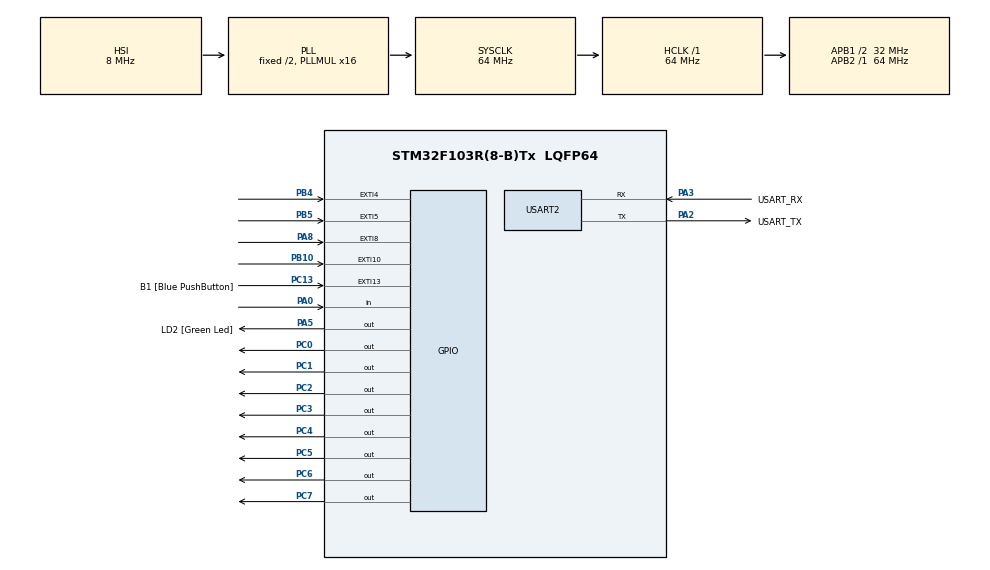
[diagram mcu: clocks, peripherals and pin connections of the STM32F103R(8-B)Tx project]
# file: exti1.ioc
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Mcu.Family=STM32F1
Mcu.Name=STM32F103R(8-B)Tx
Mcu.Package=LQFP64
NVIC.EXTI15_10_IRQn=true\:0\:0\:false\:false\:true\:true
NVIC.EXTI4_IRQn=true\:0\:0\:false\:false\:true\:true
NVIC.EXTI9_5_IRQn=true\:0\:0\:false\:false\:true\:true
NVIC.PriorityGroup=NVIC_PRIORITYGROUP_4
PA0-WKUP.Signal=GPIO_Input
PA13.GPIO_Label=TMS
PA13.Mode=Serial_Wire
PA13.Signal=SYS_JTMS-SWDIO
PA14.GPIO_Label=TCK
PA14.Mode=Serial_Wire
PA14.Signal=SYS_JTCK-SWCLK
PA2.GPIO_Label=USART_TX
PA2.GPIO_Mode=GPIO_MODE_AF_PP
PA2.GPIO_PuPd=GPIO_NOPULL
PA2.GPIO_Speed=GPIO_SPEED_FREQ_LOW
PA2.Mode=Asynchronous
PA2.Signal=USART2_TX
PA3.GPIO_Label=USART_RX
PA3.GPIO_Mode=GPIO_MODE_AF_PP
PA3.GPIO_PuPd=GPIO_NOPULL
PA3.GPIO_Speed=GPIO_SPEED_FREQ_LOW
PA3.Mode=Asynchronous
PA3.Signal=USART2_RX
PA5.GPIO_Label=LD2 [Green Led]
PA5.GPIO_ModeDefaultOutputPP=GPIO_MODE_OUTPUT_PP
PA5.GPIO_PuPd=GPIO_NOPULL
PA5.GPIO_Speed=GPIO_SPEED_FREQ_LOW
PA5.Signal=GPIO_Output
PA8.Signal=GPXTI8
PB10.Signal=GPXTI10
PB3.GPIO_Label=SWO
PB3.Signal=SYS_JTDO-TRACESWO
PB4.Signal=GPXTI4
PB5.Signal=GPXTI5
PC0.Signal=GPIO_Output
PC1.Signal=GPIO_Output
PC13-TAMPER-RTC.GPIO_Label=B1 [Blue PushButton]
PC13-TAMPER-RTC.GPIO_PuPd=GPIO_NOPULL
PC13-TAMPER-RTC.Signal=GPXTI13
PC14-OSC32_IN.Mode=LSE-External-Oscillator
PC14-OSC32_IN.Signal=RCC_OSC32_IN
PC15-OSC32_OUT.Mode=LSE-External-Oscillator
PC15-OSC32_OUT.Signal=RCC_OSC32_OUT
PC2.Signal=GPIO_Output
PC3.Signal=GPIO_Output
PC4.Signal=GPIO_Output
PC5.Signal=GPIO_Output
PC6.Signal=GPIO_Output
PC7.Signal=GPIO_Output
PD0-OSC_IN.Mode=HSE-External-Clock-Source
PD0-OSC_IN.Signal=RCC_OSC_IN
PD1-OSC_OUT.Mode=HSE-External-Clock-Source
PD1-OSC_OUT.Signal=RCC_OSC_OUT
ProjectManager.HeapSize=0x200
ProjectManager.StackSize=0x400
ProjectManager.TargetToolchain=MDK-ARM V5
RCC.AHBFreq_Value=64000000
RCC.APB1CLKDivider=RCC_HCLK_DIV2
RCC.APB1Freq_Value=32000000
RCC.APB1TimFreq_Value=64000000
RCC.APB2Freq_Value=64000000
RCC.APB2TimFreq_Value=64000000
RCC.HCLKFreq_Value=64000000
RCC.PLLMUL=RCC_PLL_MUL16
RCC.RTCClockSelection=RCC_RTCCLKSOURCE_LSE
RCC.SYSCLKFreq_VALUE=64000000
RCC.SYSCLKSource=RCC_SYSCLKSOURCE_PLLCLK
RCC.USBFreq_Value=64000000
USART2.VirtualMode=VM_ASYNC
board=NUCLEO-F103RB

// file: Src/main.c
/**
  ******************************************************************************
  * @file           : main.c
  * @brief          : Main program body
  ******************************************************************************
  ** This notice applies to any and all portions of this file
  * that are not between comment pairs USER CODE BEGIN and
  * USER CODE END. Other portions of this file, whether
  * inserted by the user or by software development tools
  * are owned by their respective copyright owners.
  *
  * COPYRIGHT(c) 2019 STMicroelectronics
  *
  * Redistribution and use in source and binary forms, with or without modification,
  * are permitted provided that the following conditions are met:
  *   1. Redistributions of source code must retain the above copyright notice,
  *      this list of conditions and the following disclaimer.
  *   2. Redistributions in binary form must reproduce the above copyright notice,
  *      this list of conditions and the following disclaimer in the documentation
  *      and/or other materials provided with the distribution.
  *   3. Neither the name of STMicroelectronics nor the names of its contributors
  *      may be used to endorse or promote products derived from this software
  *      without specific prior written permission.
  *
  * THIS SOFTWARE IS PROVIDED BY THE COPYRIGHT HOLDERS AND CONTRIBUTORS "AS IS"
  * AND ANY EXPRESS OR IMPLIED WARRANTIES, INCLUDING, BUT NOT LIMITED TO, THE
  * IMPLIED WARRANTIES OF MERCHANTABILITY AND FITNESS FOR A PARTICULAR PURPOSE ARE
  * DISCLAIMED. IN NO EVENT SHALL THE COPYRIGHT HOLDER OR CONTRIBUTORS BE LIABLE
  * FOR ANY DIRECT, INDIRECT, INCIDENTAL, SPECIAL, EXEMPLARY, OR CONSEQUENTIAL
  * DAMAGES (INCLUDING, BUT NOT LIMITED TO, PROCUREMENT OF SUBSTITUTE GOODS OR
  * SERVICES; LOSS OF USE, DATA, OR PROFITS; OR BUSINESS INTERRUPTION) HOWEVER
  * CAUSED AND ON ANY THEORY OF LIABILITY, WHETHER IN CONTRACT, STRICT LIABILITY,
  * OR TORT (INCLUDING NEGLIGENCE OR OTHERWISE) ARISING IN ANY WAY OUT OF THE USE
  * OF THIS SOFTWARE, EVEN IF ADVISED OF THE POSSIBILITY OF SUCH DAMAGE.
  *
  ******************************************************************************
  */
#include "main.h"
#include "stm32f1xx_hal.h"

UART_HandleTypeDef huart2;

/* USER CODE BEGIN PV */

int flag_sw1, flag_sw2, flag_sw3, flag_sw4 = 0;
int SW1, SW2, SW3, SW4 = 0;

/* Private variables ---------------------------------------------------------*/

/* USER CODE END PV */

void SystemClock_Config(void);
static void MX_GPIO_Init(void);
static void MX_USART2_UART_Init(void);

/* USER CODE BEGIN PFP */
/* Private function prototypes -----------------------------------------------*/

/* USER CODE END PFP */

void HAL_GPIO_EXTI_Callback(uint16_t GPIO_PIN) {
	if (GPIO_PIN == GPIO_PIN_8) flag_sw1 = 1;
	if (GPIO_PIN == GPIO_PIN_4) flag_sw2=  1;
	if (GPIO_PIN == GPIO_PIN_5) flag_sw3 = 1;
	if (GPIO_PIN == GPIO_PIN_10)flag_sw4 = 1;
}

int main(void)
{
  HAL_Init();
  SystemClock_Config();
  MX_GPIO_Init();
  MX_USART2_UART_Init();
  while (1) {
		if(flag_sw1 == 1) {
			HAL_GPIO_WritePin(GPIOC, GPIO_PIN_0 | GPIO_PIN_1, GPIO_PIN_SET);
			HAL_Delay(200);
			HAL_GPIO_WritePin(GPIOC, GPIO_PIN_0 | GPIO_PIN_1, GPIO_PIN_RESET);
			flag_sw1 = 0;
		}
		if (flag_sw2 == 1) {
			HAL_GPIO_WritePin(GPIOC, GPIO_PIN_2 | GPIO_PIN_3, GPIO_PIN_SET);
			HAL_Delay(200);
			HAL_GPIO_WritePin(GPIOC, GPIO_PIN_2 | GPIO_PIN_3, GPIO_PIN_RESET);
			flag_sw2 = 0;
		}
		if (flag_sw3 == 1) {
			HAL_GPIO_WritePin(GPIOC, GPIO_PIN_4 | GPIO_PIN_5, GPIO_PIN_SET);
			HAL_Delay(200);
			HAL_GPIO_WritePin(GPIOC, GPIO_PIN_4 | GPIO_PIN_5, GPIO_PIN_RESET);
			flag_sw3 = 0;
		}
		if (flag_sw4 == 1) {
			HAL_GPIO_WritePin(GPIOC, GPIO_PIN_6 | GPIO_PIN_7, GPIO_PIN_SET);
			HAL_Delay(200);
			HAL_GPIO_WritePin(GPIOC, GPIO_PIN_6 | GPIO_PIN_7, GPIO_PIN_RESET);
			flag_sw4 = 0;
		}
  }

}

void SystemClock_Config(void)
{

  RCC_OscInitTypeDef RCC_OscInitStruct;
  RCC_ClkInitTypeDef RCC_ClkInitStruct;

    /**Initializes the CPU, AHB and APB busses clocks
    */
  RCC_OscInitStruct.OscillatorType = RCC_OSCILLATORTYPE_HSI;
  RCC_OscInitStruct.HSIState = RCC_HSI_ON;
  RCC_OscInitStruct.HSICalibrationValue = 16;
  RCC_OscInitStruct.PLL.PLLState = RCC_PLL_ON;
  RCC_OscInitStruct.PLL.PLLSource = RCC_PLLSOURCE_HSI_DIV2;
  RCC_OscInitStruct.PLL.PLLMUL = RCC_PLL_MUL16;
  if (HAL_RCC_OscConfig(&RCC_OscInitStruct) != HAL_OK)
  {
    _Error_Handler(__FILE__, __LINE__);
  }

    /**Initializes the CPU, AHB and APB busses clocks
    */
  RCC_ClkInitStruct.ClockType = RCC_CLOCKTYPE_HCLK|RCC_CLOCKTYPE_SYSCLK
                              |RCC_CLOCKTYPE_PCLK1|RCC_CLOCKTYPE_PCLK2;
  RCC_ClkInitStruct.SYSCLKSource = RCC_SYSCLKSOURCE_PLLCLK;
  RCC_ClkInitStruct.AHBCLKDivider = RCC_SYSCLK_DIV1;
  RCC_ClkInitStruct.APB1CLKDivider = RCC_HCLK_DIV2;
  RCC_ClkInitStruct.APB2CLKDivider = RCC_HCLK_DIV1;

  if (HAL_RCC_ClockConfig(&RCC_ClkInitStruct, FLASH_LATENCY_2) != HAL_OK)
  {
    _Error_Handler(__FILE__, __LINE__);
  }

    /**Configure the Systick interrupt time
    */
  HAL_SYSTICK_Config(HAL_RCC_GetHCLKFreq()/1000);

    /**Configure the Systick
    */
  HAL_SYSTICK_CLKSourceConfig(SYSTICK_CLKSOURCE_HCLK);

  /* SysTick_IRQn interrupt configuration */
  HAL_NVIC_SetPriority(SysTick_IRQn, 0, 0);
}

/* USART2 init function */
static void MX_USART2_UART_Init(void)
{

  huart2.Instance = USART2;
  huart2.Init.BaudRate = 115200;
  huart2.Init.WordLength = UART_WORDLENGTH_8B;
  huart2.Init.StopBits = UART_STOPBITS_1;
  huart2.Init.Parity = UART_PARITY_NONE;
  huart2.Init.Mode = UART_MODE_TX_RX;
  huart2.Init.HwFlowCtl = UART_HWCONTROL_NONE;
  huart2.Init.OverSampling = UART_OVERSAMPLING_16;
  if (HAL_UART_Init(&huart2) != HAL_OK)
  {
    _Error_Handler(__FILE__, __LINE__);
  }

}

/** Configure pins as
        * Analog
        * Input
        * Output
        * EVENT_OUT
        * EXTI
*/
static void MX_GPIO_Init(void)
{

  GPIO_InitTypeDef GPIO_InitStruct;

  /* GPIO Ports Clock Enable */
  __HAL_RCC_GPIOC_CLK_ENABLE();
  __HAL_RCC_GPIOD_CLK_ENABLE();
  __HAL_RCC_GPIOA_CLK_ENABLE();
  __HAL_RCC_GPIOB_CLK_ENABLE();

  /*Configure GPIO pin Output Level */
  HAL_GPIO_WritePin(GPIOC, GPIO_PIN_0|GPIO_PIN_1|GPIO_PIN_2|GPIO_PIN_3
                          |GPIO_PIN_4|GPIO_PIN_5|GPIO_PIN_6|GPIO_PIN_7, GPIO_PIN_RESET);

  /*Configure GPIO pin Output Level */
  HAL_GPIO_WritePin(LD2_GPIO_Port, LD2_Pin, GPIO_PIN_RESET);

  /*Configure GPIO pin : B1_Pin */
  GPIO_InitStruct.Pin = B1_Pin;
  GPIO_InitStruct.Mode = GPIO_MODE_IT_RISING;
  GPIO_InitStruct.Pull = GPIO_NOPULL;
  HAL_GPIO_Init(B1_GPIO_Port, &GPIO_InitStruct);

  /*Configure GPIO pins : PC0 PC1 PC2 PC3
                           PC4 PC5 PC6 PC7 */
  GPIO_InitStruct.Pin = GPIO_PIN_0|GPIO_PIN_1|GPIO_PIN_2|GPIO_PIN_3
                          |GPIO_PIN_4|GPIO_PIN_5|GPIO_PIN_6|GPIO_PIN_7;
  GPIO_InitStruct.Mode = GPIO_MODE_OUTPUT_PP;
  GPIO_InitStruct.Pull = GPIO_NOPULL;
  GPIO_InitStruct.Speed = GPIO_SPEED_FREQ_LOW;
  HAL_GPIO_Init(GPIOC, &GPIO_InitStruct);

  /*Configure GPIO pin : PA0 */
  GPIO_InitStruct.Pin = GPIO_PIN_0;
  GPIO_InitStruct.Mode = GPIO_MODE_INPUT;
  GPIO_InitStruct.Pull = GPIO_NOPULL;
  HAL_GPIO_Init(GPIOA, &GPIO_InitStruct);

  /*Configure GPIO pin : LD2_Pin */
  GPIO_InitStruct.Pin = LD2_Pin;
  GPIO_InitStruct.Mode = GPIO_MODE_OUTPUT_PP;
  GPIO_InitStruct.Pull = GPIO_NOPULL;
  GPIO_InitStruct.Speed = GPIO_SPEED_FREQ_LOW;
  HAL_GPIO_Init(LD2_GPIO_Port, &GPIO_InitStruct);

  /*Configure GPIO pins : PB10 PB4 PB5 */
  GPIO_InitStruct.Pin = GPIO_PIN_10|GPIO_PIN_4|GPIO_PIN_5;
  GPIO_InitStruct.Mode = GPIO_MODE_IT_RISING;
  GPIO_InitStruct.Pull = GPIO_NOPULL;
  HAL_GPIO_Init(GPIOB, &GPIO_InitStruct);

  /*Configure GPIO pin : PA8 */
  GPIO_InitStruct.Pin = GPIO_PIN_8;
  GPIO_InitStruct.Mode = GPIO_MODE_IT_RISING;
  GPIO_InitStruct.Pull = GPIO_NOPULL;
  HAL_GPIO_Init(GPIOA, &GPIO_InitStruct);

  /* EXTI interrupt init*/
  HAL_NVIC_SetPriority(EXTI4_IRQn, 0, 0);
  HAL_NVIC_EnableIRQ(EXTI4_IRQn);

  HAL_NVIC_SetPriority(EXTI9_5_IRQn, 0, 0);
  HAL_NVIC_EnableIRQ(EXTI9_5_IRQn);

  HAL_NVIC_SetPriority(EXTI15_10_IRQn, 0, 0);
  HAL_NVIC_EnableIRQ(EXTI15_10_IRQn);

}

void _Error_Handler(char *file, int line)
{
  while(1)
  {
  }
}

/************************ (C) COPYRIGHT STMicroelectronics *****END OF FILE****/
